AUTOSAR XML (schema 4-0-3)
package /Sensors
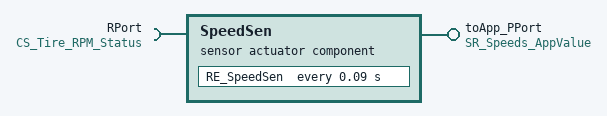
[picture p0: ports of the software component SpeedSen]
  sensor actuator sw component type SpeedSen
    require port RPort: required-interface=CS_Tire_RPM_Status
    provide port toApp_PPort: provided-interface=SR_Speeds_AppValue
    behavior IB_SpeedSen
      timing event SpeedSensorEvnet: start-on-event=RE_SpeedSen, period=0.09
      runnable RE_SpeedSen: symbol=RE_SpeedSen_func
        data-send-points:
          4 x access:
            DSP_forntleft_0: accessed-variable=toApp_PPort.frontleft
            DSP_forntright_0: accessed-variable=toApp_PPort.frontright
            DSP_backleft_0: accessed-variable=toApp_PPort.backleft
            DSP_backright_0: accessed-variable=toApp_PPort.backright
        sync call SynchronousServerCallPoint_0: operation=RPort.get_Tire_RPM
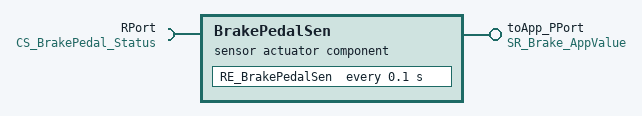
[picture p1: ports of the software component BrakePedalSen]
  sensor actuator sw component type BrakePedalSen
    require port RPort: required-interface=CS_BrakePedal_Status
    provide port toApp_PPort: provided-interface=SR_Brake_AppValue
    behavior IB_BrakePedalSen
      timing event TimingEvent_0: start-on-event=RE_BrakePedalSen, period=0.1
      runnable RE_BrakePedalSen: symbol=RE_BrakePedalSen_func
        data-send-points:
          access DSP_brake_value_0: accessed-variable=toApp_PPort.brake_value
        sync call SynchronousServerCallPoint_0: operation=RPort.get_BrakePedal_Status
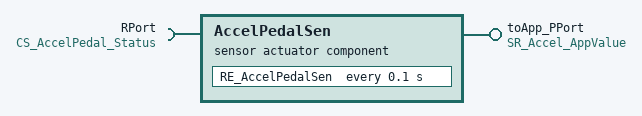
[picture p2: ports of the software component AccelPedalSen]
  sensor actuator sw component type AccelPedalSen
    require port RPort: required-interface=CS_AccelPedal_Status
    provide port toApp_PPort: provided-interface=SR_Accel_AppValue
    behavior IB_AccelPedalSen
      timing event TimingEvent_0: start-on-event=RE_AccelPedalSen, period=0.1
      runnable RE_AccelPedalSen: symbol=RE_AccelPedalSen_func
        data-send-points:
          access DSP_accel_value_0: accessed-variable=toApp_PPort.accel_value
        sync call SynchronousServerCallPoint_0: operation=RPort.get_AccelPedal_Status
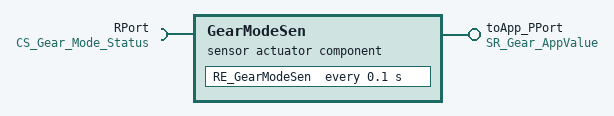
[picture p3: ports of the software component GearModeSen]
  sensor actuator sw component type GearModeSen
    require port RPort: required-interface=CS_Gear_Mode_Status
    provide port toApp_PPort: provided-interface=SR_Gear_AppValue
    behavior IB_GearModeSen
      timing event TimingEvent_0: start-on-event=RE_GearModeSen, period=0.1
      runnable RE_GearModeSen: symbol=RE_GearModeSen_func
        data-send-points:
          access DSP_gear_value_0: accessed-variable=toApp_PPort.gear_value
        sync call SynchronousServerCallPoint_0: operation=RPort.get_Gear_Mode
  4 x sender receiver interface:
    SR_Speeds_AppValue
      4 x data, all with type=float32:
        frontleft
        frontright
        backleft
        backright
    SR_Accel_AppValue
      data accel_value: type=sint8
    SR_Brake_AppValue
      data brake_value: type=sint8
    SR_Gear_AppValue
      data gear_value: type=sint8
